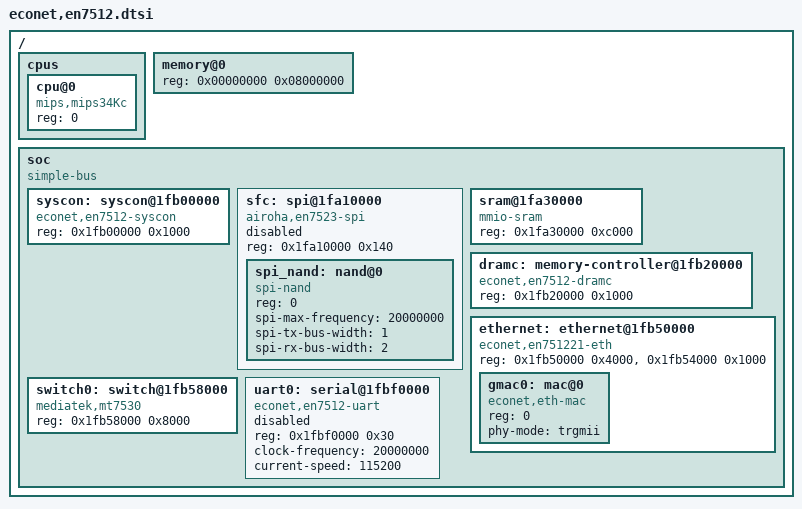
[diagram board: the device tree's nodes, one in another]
// SPDX-License-Identifier: GPL-2.0+

/ {
	#address-cells = <1>;
	#size-cells = <1>;

	cpus {
		#address-cells = <1>;
		#size-cells = <0>;

		cpu@0 {
			compatible = "mips,mips34Kc";
			device_type = "cpu";
			reg = <0>;
		};
	};

	memory@0 {
		device_type = "memory";
		reg = <0x00000000 0x08000000>;
	};

	soc {
		compatible = "simple-bus";
		#address-cells = <1>;
		#size-cells = <1>;
		ranges;

		syscon: syscon@1fb00000 {
			compatible = "econet,en7512-syscon", "syscon";
			reg = <0x1fb00000 0x1000>;
		};

		sfc: spi@1fa10000 {
			compatible = "airoha,en7523-spi";
			reg = <0x1fa10000 0x140>;
			#address-cells = <1>;
			#size-cells = <0>;
			status = "disabled";

			spi_nand: nand@0 {
				compatible = "spi-nand";
				reg = <0>;
				spi-max-frequency = <20000000>;
				spi-tx-bus-width = <1>;
				spi-rx-bus-width = <2>;
			};
		};

		sram@1fa30000 {
			compatible = "mmio-sram";
			reg = <0x1fa30000 0xc000>;
		};

		dramc: memory-controller@1fb20000 {
			compatible = "econet,en7512-dramc";
			reg = <0x1fb20000 0x1000>;
		};

		ethernet: ethernet@1fb50000 {
			compatible = "econet,en751221-eth";
			reg = <0x1fb50000 0x4000>,
			      <0x1fb54000 0x1000>;
			reg-names = "fe", "qdma0";
			#address-cells = <1>;
			#size-cells = <0>;

			gmac0: mac@0 {
				compatible = "econet,eth-mac";
				reg = <0>;
				phy-mode = "trgmii";
			};
		};

		switch0: switch@1fb58000 {
			compatible = "mediatek,mt7530";
			reg = <0x1fb58000 0x8000>;
		};

		uart0: serial@1fbf0000 {
			compatible = "econet,en7512-uart";
			reg = <0x1fbf0000 0x30>;
			clock-frequency = <20000000>;
			current-speed = <115200>;
			status = "disabled";
		};
	};
};
